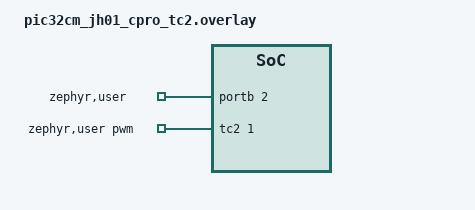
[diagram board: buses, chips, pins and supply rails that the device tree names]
/*
 * SPDX-FileCopyrightText: Copyright 2026 Microchip Technology Inc.
 * SPDX-License-Identifier: Apache-2.0
 */

/* connect PB3 to PB2 */

#define PWM_NODE    tc2
#define PWM_PINCTRL tc2_pwm_default
#include "mchp_pwm_loopback_support.dtsi"

/ {
	zephyr,user {
		pwms = <&tc2 1 PWM_MSEC(20) 0>;
		gpios = <&portb 2 GPIO_ACTIVE_HIGH>;
	};
};

&portb {
	status = "okay";
};

&pinctrl {
	tc2_pwm_default: tc2_pwm_default {
		group1 {
			pinmux = <PB3E_TC2_WO1>;
		};
	};
};
